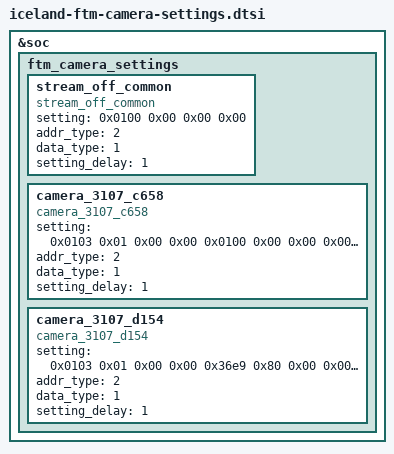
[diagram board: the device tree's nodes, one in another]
&soc {
    ftm_camera_settings {
        stream_off_common {
            compatible = "stream_off_common";
            setting = <
                0x0100  0x00  0x00  0x00
            >;
            addr_type       = <2>;
            data_type       = <1>;
            setting_delay   = <1>;

        };

        camera_3107_c658{
            compatible = "camera_3107_c658";
            setting = <
                0x0103  0x01  0x00  0x00
                0x0100  0x00  0x00  0x00
                0x36e9  0x80  0x00  0x00
                0x37f9  0x80  0x00  0x00
                0x36ea  0x17  0x00  0x00
                0x36eb  0x0c  0x00  0x00
                0x36ec  0x4b  0x00  0x00
                0x36ed  0x18  0x00  0x00
                0x37fa  0x19  0x00  0x00
                0x37fb  0xb2  0x00  0x00
                0x37fc  0x10  0x00  0x00
                0x37fd  0x3a  0x00  0x00
                0x301f  0x60  0x00  0x00
                0x320c  0x04  0x00  0x00
                0x320d  0xe2  0x00  0x00
                0x320e  0x0c  0x00  0x00
                0x320f  0x80  0x00  0x00
                0x3279  0x10  0x00  0x00
                0x3301  0x07  0x00  0x00
                0x3302  0x18  0x00  0x00
                0x3304  0x38  0x00  0x00
                0x3306  0x58  0x00  0x00
                0x3308  0x0c  0x00  0x00
                0x3309  0x80  0x00  0x00
                0x330b  0xb8  0x00  0x00
                0x330d  0x10  0x00  0x00
                0x330e  0x2b  0x00  0x00
                0x3314  0x15  0x00  0x00
                0x331c  0x04  0x00  0x00
                0x331e  0x29  0x00  0x00
                0x331f  0x71  0x00  0x00
                0x3320  0x08  0x00  0x00
                0x3323  0x04  0x00  0x00
                0x3333  0x10  0x00  0x00
                0x3334  0x40  0x00  0x00
                0x334a  0x82  0x00  0x00
                0x3351  0x06  0x00  0x00
                0x335d  0x60  0x00  0x00
                0x3364  0x56  0x00  0x00
                0x337f  0x13  0x00  0x00
                0x3390  0x09  0x00  0x00
                0x3391  0x0f  0x00  0x00
                0x3392  0x1f  0x00  0x00
                0x3393  0x10  0x00  0x00
                0x3394  0x1c  0x00  0x00
                0x3395  0x20  0x00  0x00
                0x33ac  0x0a  0x00  0x00
                0x33ad  0x14  0x00  0x00
                0x33ae  0x14  0x00  0x00
                0x33af  0x60  0x00  0x00
                0x33b0  0x0f  0x00  0x00
                0x33b2  0x50  0x00  0x00
                0x33b3  0x28  0x00  0x00
                0x349f  0x1e  0x00  0x00
                0x34a6  0x08  0x00  0x00
                0x34a7  0x09  0x00  0x00
                0x34a8  0x18  0x00  0x00
                0x34a9  0x18  0x00  0x00
                0x34f8  0x0f  0x00  0x00
                0x34f9  0x18  0x00  0x00
                0x3630  0xc6  0x00  0x00
                0x3637  0x47  0x00  0x00
                0x363c  0x8d  0x00  0x00
                0x3650  0x31  0x00  0x00
                0x3651  0x9d  0x00  0x00
                0x3652  0x32  0x00  0x00
                0x3653  0x23  0x00  0x00
                0x3654  0x31  0x00  0x00
                0x3670  0x0c  0x00  0x00
                0x367b  0x56  0x00  0x00
                0x367c  0x67  0x00  0x00
                0x367d  0x67  0x00  0x00
                0x367e  0x08  0x00  0x00
                0x367f  0x0f  0x00  0x00
                0x3690  0x84  0x00  0x00
                0x3691  0x87  0x00  0x00
                0x3692  0x8e  0x00  0x00
                0x3693  0xb5  0x00  0x00
                0x3694  0x09  0x00  0x00
                0x3695  0x0b  0x00  0x00
                0x3696  0x0f  0x00  0x00
                0x3697  0x8b  0x00  0x00
                0x3698  0x8d  0x00  0x00
                0x3699  0x8d  0x00  0x00
                0x369a  0x08  0x00  0x00
                0x369b  0x0f  0x00  0x00
                0x370f  0x01  0x00  0x00
                0x3724  0x41  0x00  0x00
                0x3771  0x03  0x00  0x00
                0x3772  0x03  0x00  0x00
                0x3773  0x63  0x00  0x00
                0x377a  0x08  0x00  0x00
                0x377b  0x0f  0x00  0x00
                0x3900  0x0d  0x00  0x00
                0x3903  0x20  0x00  0x00
                0x3905  0x0c  0x00  0x00
                0x3908  0x40  0x00  0x00
                0x391a  0x30  0x00  0x00
                0x391b  0x21  0x00  0x00
                0x391c  0x13  0x00  0x00
                0x391d  0x00  0x00  0x00
                0x391f  0x41  0x00  0x00
                0x3926  0xe0  0x00  0x00
                0x393f  0x80  0x00  0x00
                0x3940  0x00  0x00  0x00
                0x3941  0x00  0x00  0x00
                0x3942  0x00  0x00  0x00
                0x3943  0x7c  0x00  0x00
                0x3944  0x79  0x00  0x00
                0x3945  0x7d  0x00  0x00
                0x3946  0x7d  0x00  0x00
                0x39dd  0x00  0x00  0x00
                0x39de  0x04  0x00  0x00
                0x39e7  0x04  0x00  0x00
                0x39e8  0x03  0x00  0x00
                0x39e9  0x80  0x00  0x00
                0x3e00  0x00  0x00  0x00
                0x3e01  0x0f  0x00  0x00
                0x3e02  0x90  0x00  0x00
                0x3f08  0x0a  0x00  0x00
                0x4401  0x13  0x00  0x00
                0x4402  0x03  0x00  0x00
                0x4403  0x0c  0x00  0x00
                0x4404  0x24  0x00  0x00
                0x4405  0x2f  0x00  0x00
                0x440c  0x3c  0x00  0x00
                0x440d  0x3c  0x00  0x00
                0x440e  0x2d  0x00  0x00
                0x440f  0x4b  0x00  0x00
                0x4413  0x01  0x00  0x00
                0x441b  0x18  0x00  0x00
                0x4509  0x18  0x00  0x00
                0x450d  0x13  0x00  0x00
                0x4800  0x24  0x00  0x00
                0x4819  0x71  0x00  0x00
                0x4837  0x18  0x00  0x00
                0x5000  0x1e  0x00  0x00
                0x5002  0x00  0x00  0x00
                0x5015  0x41  0x00  0x00
                0x550e  0x00  0x00  0x00
                0x550f  0x7a  0x00  0x00
                0x5780  0x76  0x00  0x00
                0x5784  0x08  0x00  0x00
                0x5787  0x0a  0x00  0x00
                0x5788  0x0a  0x00  0x00
                0x5789  0x0a  0x00  0x00
                0x578a  0x0a  0x00  0x00
                0x578b  0x0a  0x00  0x00
                0x578c  0x0a  0x00  0x00
                0x578d  0x40  0x00  0x00
                0x5790  0x08  0x00  0x00
                0x5791  0x04  0x00  0x00
                0x5792  0x04  0x00  0x00
                0x5793  0x08  0x00  0x00
                0x5794  0x04  0x00  0x00
                0x5795  0x04  0x00  0x00
                0x5799  0x44  0x00  0x00
                0x57a6  0x1c  0x00  0x00
                0x57aa  0xeb  0x00  0x00
                0x57ab  0x7f  0x00  0x00
                0x57ac  0x00  0x00  0x00
                0x57ad  0x00  0x00  0x00
                0x58e0  0xb4  0x00  0x00
                0x36e9  0x25  0x00  0x00
                0x37f9  0x24  0x00  0x00
                0x3200  0x00  0x00  0x00
                0x3201  0x00  0x00  0x00
                0x3202  0x00  0x00  0x00
                0x3203  0x00  0x00  0x00
                0x3204  0x10  0x00  0x00
                0x3205  0x7f  0x00  0x00
                0x3206  0x0c  0x00  0x00
                0x3207  0x3f  0x00  0x00
                0x3208  0x10  0x00  0x00
                0x3209  0x40  0x00  0x00
                0x320a  0x0c  0x00  0x00
                0x320b  0x30  0x00  0x00
                0x3210  0x00  0x00  0x00
                0x3211  0x20  0x00  0x00
                0x3212  0x00  0x00  0x00
                0x3213  0x08  0x00  0x00
                0x3215  0x11  0x00  0x00
                0x3220  0x00  0x00  0x00
                0x3221  0x66  0x00  0x00
                0x5000  0x1e  0x00  0x00
                0x5900  0x01  0x00  0x00
                0x5901  0x00  0x00  0x00
                0x0100  0x01  0x00  0x00
            >;
            addr_type       = <2>;
            data_type       = <1>;
            setting_delay   = <1>;
        };

        camera_3107_d154{
            compatible = "camera_3107_d154";
            setting = <
                0x0103  0x01  0x00  0x00
                0x36e9  0x80  0x00  0x00
                0x37f9  0x80  0x00  0x00
                0x36ea  0x0b  0x00  0x00
                0x36eb  0x0c  0x00  0x00
                0x36ec  0x5a  0x00  0x00
                0x36ed  0x28  0x00  0x00
                0x37fa  0x0b  0x00  0x00
                0x37fb  0x71  0x00  0x00
                0x37fc  0x10  0x00  0x00
                0x37fd  0x28  0x00  0x00
                0x36e9  0x22  0x00  0x00
                0x37f9  0x24  0x00  0x00
                0x301f  0x44  0x00  0x00
                0x3205  0xc7  0x00  0x00
                0x3211  0x04  0x00  0x00
                0x3221  0x66  0x00  0x00
                0x3215  0x11  0x00  0x00
                0x3220  0x00  0x00  0x00
                0x3221  0x66  0x00  0x00
                0x3270  0x00  0x00  0x00
                0x3271  0x00  0x00  0x00
                0x3272  0x00  0x00  0x00
                0x3273  0x03  0x00  0x00
                0x3301  0x08  0x00  0x00
                0x3303  0x10  0x00  0x00
                0x3306  0x84  0x00  0x00
                0x3307  0x04  0x00  0x00
                0x3309  0x88  0x00  0x00
                0x330a  0x01  0x00  0x00
                0x330b  0x0c  0x00  0x00
                0x330c  0x10  0x00  0x00
                0x330d  0x18  0x00  0x00
                0x330e  0x30  0x00  0x00
                0x330f  0x04  0x00  0x00
                0x3310  0x02  0x00  0x00
                0x3314  0x15  0x00  0x00
                0x3317  0x04  0x00  0x00
                0x331f  0x79  0x00  0x00
                0x3326  0x0e  0x00  0x00
                0x3327  0x0a  0x00  0x00
                0x3329  0x0b  0x00  0x00
                0x3333  0x10  0x00  0x00
                0x3334  0x40  0x00  0x00
                0x3347  0x0f  0x00  0x00
                0x335d  0x60  0x00  0x00
                0x3364  0x56  0x00  0x00
                0x336c  0xce  0x00  0x00
                0x3390  0x08  0x00  0x00
                0x3391  0x09  0x00  0x00
                0x3392  0x0f  0x00  0x00
                0x3393  0x10  0x00  0x00
                0x3394  0x20  0x00  0x00
                0x3395  0x28  0x00  0x00
                0x33ad  0x3c  0x00  0x00
                0x33af  0x70  0x00  0x00
                0x33b2  0x70  0x00  0x00
                0x33b3  0x40  0x00  0x00
                0x349f  0x1e  0x00  0x00
                0x34a6  0x09  0x00  0x00
                0x34a7  0x0f  0x00  0x00
                0x34a8  0x30  0x00  0x00
                0x34a9  0x20  0x00  0x00
                0x34f8  0x1f  0x00  0x00
                0x34f9  0x08  0x00  0x00
                0x3637  0x43  0x00  0x00
                0x363c  0x8d  0x00  0x00
                0x3670  0x4a  0x00  0x00
                0x3674  0xf6  0x00  0x00
                0x3675  0xdc  0x00  0x00
                0x3676  0xcc  0x00  0x00
                0x367c  0x09  0x00  0x00
                0x367d  0x0f  0x00  0x00
                0x3690  0x34  0x00  0x00
                0x3691  0x44  0x00  0x00
                0x3692  0x55  0x00  0x00
                0x3698  0x86  0x00  0x00
                0x3699  0x8d  0x00  0x00
                0x369a  0x99  0x00  0x00
                0x369b  0xb7  0x00  0x00
                0x369c  0x0f  0x00  0x00
                0x369d  0x1f  0x00  0x00
                0x36a2  0x09  0x00  0x00
                0x36a3  0x0b  0x00  0x00
                0x36a4  0x0f  0x00  0x00
                0x36b0  0x48  0x00  0x00
                0x36b1  0x38  0x00  0x00
                0x36b2  0x41  0x00  0x00
                0x370f  0x01  0x00  0x00
                0x3724  0xc1  0x00  0x00
                0x3771  0x07  0x00  0x00
                0x3772  0x03  0x00  0x00
                0x3773  0x63  0x00  0x00
                0x377a  0x08  0x00  0x00
                0x377b  0x0f  0x00  0x00
                0x3901  0x04  0x00  0x00
                0x3903  0xa0  0x00  0x00
                0x3905  0x8d  0x00  0x00
                0x391d  0x01  0x00  0x00
                0x3926  0x23  0x00  0x00
                0x393f  0x80  0x00  0x00
                0x3940  0x00  0x00  0x00
                0x3941  0x00  0x00  0x00
                0x3942  0x00  0x00  0x00
                0x3943  0x63  0x00  0x00
                0x3944  0x5f  0x00  0x00
                0x3c04  0x01  0x00  0x00
                0x3e00  0x01  0x00  0x00
                0x3e01  0x38  0x00  0x00
                0x3e02  0x00  0x00  0x00
                0x4401  0x13  0x00  0x00
                0x4402  0x03  0x00  0x00
                0x4403  0x0e  0x00  0x00
                0x4404  0x28  0x00  0x00
                0x4405  0x34  0x00  0x00
                0x4407  0x0e  0x00  0x00
                0x440c  0x42  0x00  0x00
                0x440d  0x42  0x00  0x00
                0x440e  0x32  0x00  0x00
                0x440f  0x53  0x00  0x00
                0x4412  0x01  0x00  0x00
                0x4424  0x01  0x00  0x00
                0x442d  0x00  0x00  0x00
                0x442e  0x00  0x00  0x00
                0x4509  0x28  0x00  0x00
                0x450d  0x18  0x00  0x00
                0x451d  0xc8  0x00  0x00
                0x4526  0x09  0x00  0x00
                0x5000  0x0e  0x00  0x00
                0x5900  0x01  0x00  0x00
                0x5901  0x00  0x00  0x00
                0x550e  0x00  0x00  0x00
                0x550f  0xBC  0x00  0x00
                0x5780  0x66  0x00  0x00
                0x578d  0x40  0x00  0x00
                0x57aa  0xeb  0x00  0x00
                0x3200  0x00  0x00  0x00
                0x3201  0x00  0x00  0x00
                0x3202  0x00  0x00  0x00
                0x3203  0x00  0x00  0x00
                0x3204  0x0c  0x00  0x00
                0x3205  0xc7  0x00  0x00
                0x3206  0x09  0x00  0x00
                0x3207  0x9f  0x00  0x00
                0x3208  0x0c  0x00  0x00
                0x3209  0xc0  0x00  0x00
                0x320a  0x09  0x00  0x00
                0x320b  0x90  0x00  0x00
                0x3210  0x00  0x00  0x00
                0x3211  0x04  0x00  0x00
                0x3212  0x00  0x00  0x00
                0x3213  0x08  0x00  0x00
                0x3215  0x11  0x00  0x00
                0x3220  0x00  0x00  0x00
                0x3221  0x66  0x00  0x00
                0x5000  0x0e  0x00  0x00
                0x5900  0x01  0x00  0x00
                0x5901  0x00  0x00  0x00
                0x0100  0x01  0x00  0x00
            >;
            addr_type       = <2>;
            data_type       = <1>;
            setting_delay   = <1>;
        };
    };
};
